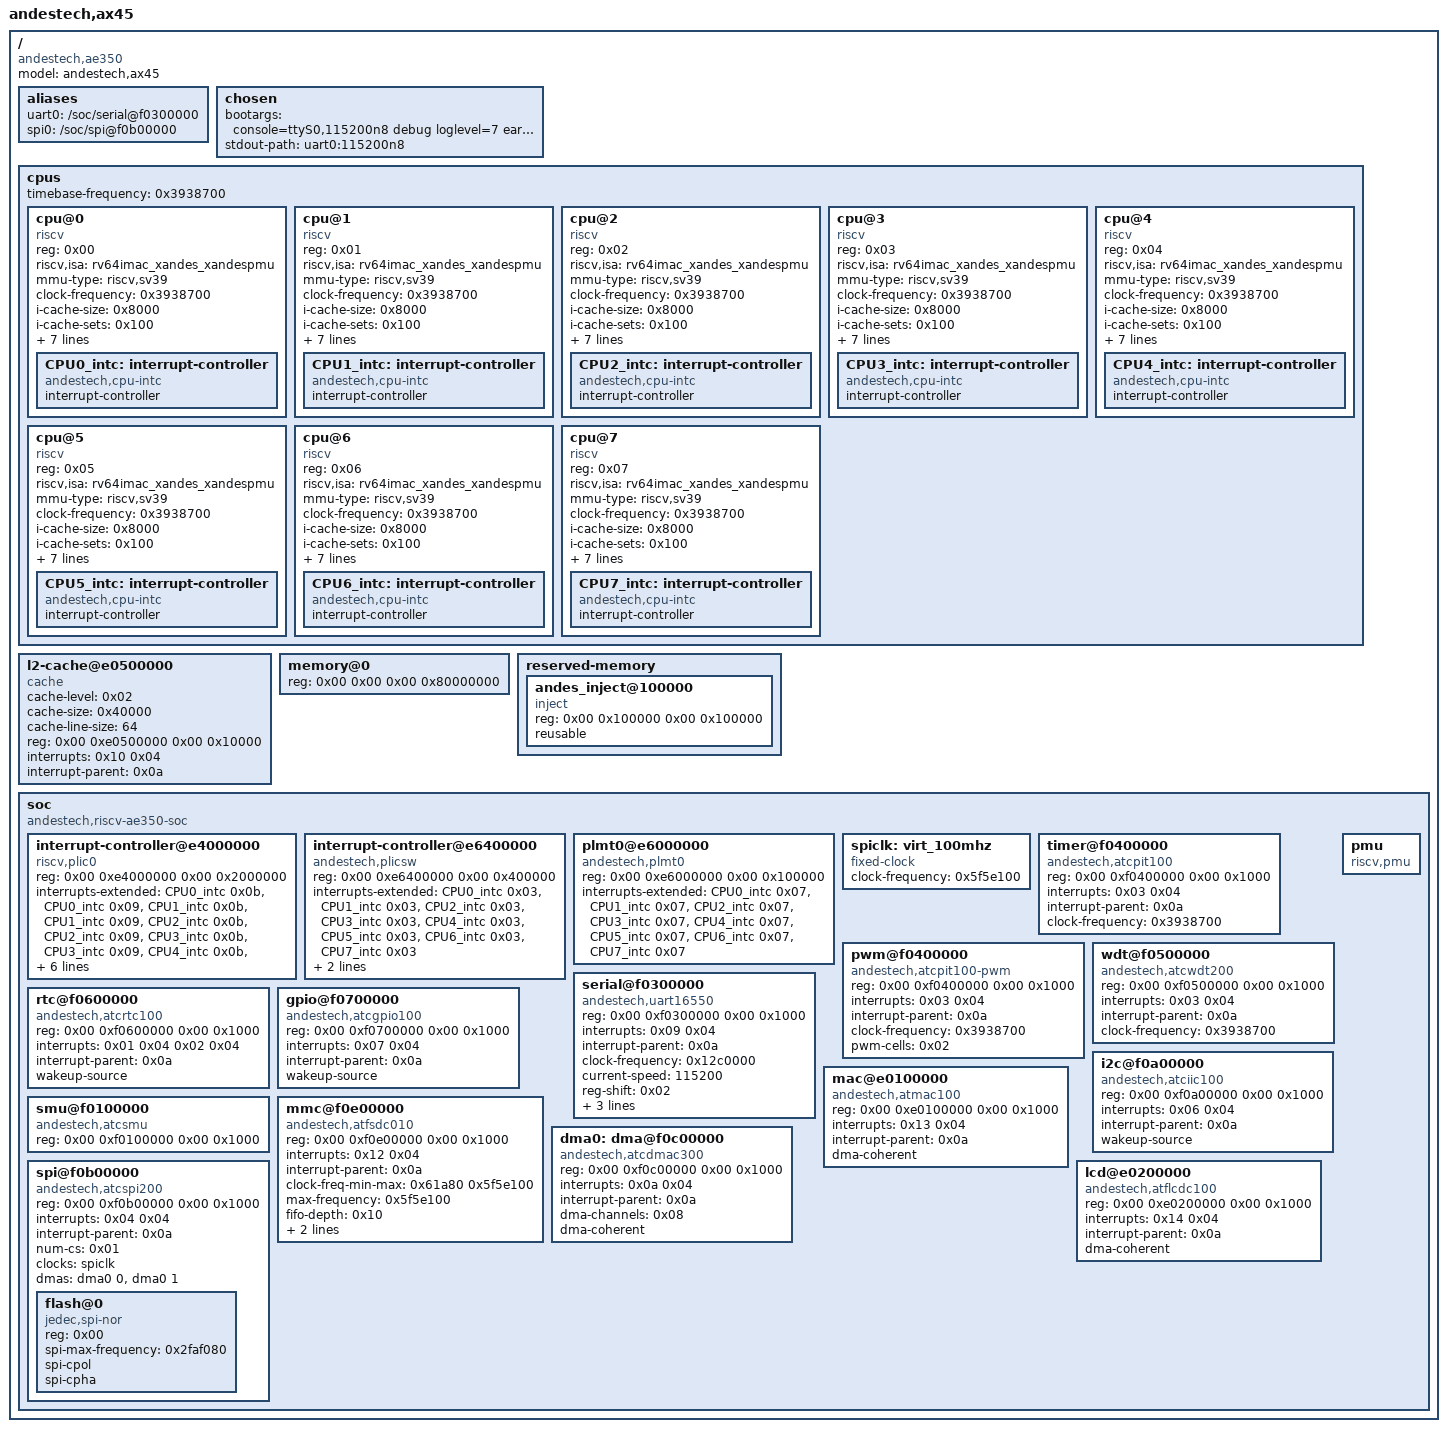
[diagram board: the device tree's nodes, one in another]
/dts-v1/;

/ {
	#address-cells = <0x02>;
	#size-cells = <0x02>;
	compatible = "andestech,ae350";
	model = "andestech,ax45";

	aliases {
		uart0 = "/soc/serial@f0300000";
		spi0 = "/soc/spi@f0b00000";
	};

	chosen {
		bootargs = "console=ttyS0,115200n8 debug loglevel=7 earlycon=sbi";
		stdout-path = "uart0:115200n8";
	};

	cpus {
		#address-cells = <0x01>;
		#size-cells = <0x00>;
		timebase-frequency = <0x3938700>;

		cpu@0 {
			device_type = "cpu";
			reg = <0x00>;
			status = "okay";
			compatible = "riscv";
			riscv,isa = "rv64imac_xandes_xandespmu";
			mmu-type = "riscv,sv39";
			clock-frequency = <0x3938700>;
			i-cache-size = <0x8000>;
			i-cache-sets = <0x100>;
			i-cache-line-size = <0x40>;
			i-cache-block-size = <0x40>;
			d-cache-size = <0x8000>;
			d-cache-sets = <0x80>;
			d-cache-line-size = <0x40>;
			d-cache-block-size = <0x40>;
			next-level-cache = <0x01>;

			CPU0_intc: interrupt-controller {
				#interrupt-cells = <0x01>;
				interrupt-controller;
				compatible = "andestech,cpu-intc", "riscv,cpu-intc";
			};
		};

		cpu@1 {
			device_type = "cpu";
			reg = <0x01>;
			status = "okay";
			compatible = "riscv";
			riscv,isa = "rv64imac_xandes_xandespmu";
			mmu-type = "riscv,sv39";
			clock-frequency = <0x3938700>;
			i-cache-size = <0x8000>;
			i-cache-sets = <0x100>;
			i-cache-line-size = <0x40>;
			i-cache-block-size = <0x40>;
			d-cache-size = <0x8000>;
			d-cache-sets = <0x80>;
			d-cache-line-size = <0x40>;
			d-cache-block-size = <0x40>;
			next-level-cache = <0x01>;

			CPU1_intc: interrupt-controller {
				#interrupt-cells = <0x01>;
				interrupt-controller;
				compatible = "andestech,cpu-intc", "riscv,cpu-intc";
			};
		};

		cpu@2 {
			device_type = "cpu";
			reg = <0x02>;
			status = "okay";
			compatible = "riscv";
			riscv,isa = "rv64imac_xandes_xandespmu";
			mmu-type = "riscv,sv39";
			clock-frequency = <0x3938700>;
			i-cache-size = <0x8000>;
			i-cache-sets = <0x100>;
			i-cache-line-size = <0x40>;
			i-cache-block-size = <0x40>;
			d-cache-size = <0x8000>;
			d-cache-sets = <0x80>;
			d-cache-line-size = <0x40>;
			d-cache-block-size = <0x40>;
			next-level-cache = <0x01>;

			CPU2_intc: interrupt-controller {
				#interrupt-cells = <0x01>;
				interrupt-controller;
				compatible = "andestech,cpu-intc", "riscv,cpu-intc";
			};
		};

		cpu@3 {
			device_type = "cpu";
			reg = <0x03>;
			status = "okay";
			compatible = "riscv";
			riscv,isa = "rv64imac_xandes_xandespmu";
			mmu-type = "riscv,sv39";
			clock-frequency = <0x3938700>;
			i-cache-size = <0x8000>;
			i-cache-sets = <0x100>;
			i-cache-line-size = <0x40>;
			i-cache-block-size = <0x40>;
			d-cache-size = <0x8000>;
			d-cache-sets = <0x80>;
			d-cache-line-size = <0x40>;
			d-cache-block-size = <0x40>;
			next-level-cache = <0x01>;

			CPU3_intc: interrupt-controller {
				#interrupt-cells = <0x01>;
				interrupt-controller;
				compatible = "andestech,cpu-intc", "riscv,cpu-intc";
			};
		};

		cpu@4 {
			device_type = "cpu";
			reg = <0x04>;
			status = "okay";
			compatible = "riscv";
			riscv,isa = "rv64imac_xandes_xandespmu";
			mmu-type = "riscv,sv39";
			clock-frequency = <0x3938700>;
			i-cache-size = <0x8000>;
			i-cache-sets = <0x100>;
			i-cache-line-size = <0x40>;
			i-cache-block-size = <0x40>;
			d-cache-size = <0x8000>;
			d-cache-sets = <0x80>;
			d-cache-line-size = <0x40>;
			d-cache-block-size = <0x40>;
			next-level-cache = <0x01>;

			CPU4_intc: interrupt-controller {
				#interrupt-cells = <0x01>;
				interrupt-controller;
				compatible = "andestech,cpu-intc", "riscv,cpu-intc";
			};
		};

		cpu@5 {
			device_type = "cpu";
			reg = <0x05>;
			status = "okay";
			compatible = "riscv";
			riscv,isa = "rv64imac_xandes_xandespmu";
			mmu-type = "riscv,sv39";
			clock-frequency = <0x3938700>;
			i-cache-size = <0x8000>;
			i-cache-sets = <0x100>;
			i-cache-line-size = <0x40>;
			i-cache-block-size = <0x40>;
			d-cache-size = <0x8000>;
			d-cache-sets = <0x80>;
			d-cache-line-size = <0x40>;
			d-cache-block-size = <0x40>;
			next-level-cache = <0x01>;

			CPU5_intc: interrupt-controller {
				#interrupt-cells = <0x01>;
				interrupt-controller;
				compatible = "andestech,cpu-intc", "riscv,cpu-intc";
			};
		};

		cpu@6 {
			device_type = "cpu";
			reg = <0x06>;
			status = "okay";
			compatible = "riscv";
			riscv,isa = "rv64imac_xandes_xandespmu";
			mmu-type = "riscv,sv39";
			clock-frequency = <0x3938700>;
			i-cache-size = <0x8000>;
			i-cache-sets = <0x100>;
			i-cache-line-size = <0x40>;
			i-cache-block-size = <0x40>;
			d-cache-size = <0x8000>;
			d-cache-sets = <0x80>;
			d-cache-line-size = <0x40>;
			d-cache-block-size = <0x40>;
			next-level-cache = <0x01>;

			CPU6_intc: interrupt-controller {
				#interrupt-cells = <0x01>;
				interrupt-controller;
				compatible = "andestech,cpu-intc", "riscv,cpu-intc";
			};
		};

		cpu@7 {
			device_type = "cpu";
			reg = <0x07>;
			status = "okay";
			compatible = "riscv";
			riscv,isa = "rv64imac_xandes_xandespmu";
			mmu-type = "riscv,sv39";
			clock-frequency = <0x3938700>;
			i-cache-size = <0x8000>;
			i-cache-sets = <0x100>;
			i-cache-line-size = <0x40>;
			i-cache-block-size = <0x40>;
			d-cache-size = <0x8000>;
			d-cache-sets = <0x80>;
			d-cache-line-size = <0x40>;
			d-cache-block-size = <0x40>;
			next-level-cache = <0x01>;

			CPU7_intc: interrupt-controller {
				#interrupt-cells = <0x01>;
				interrupt-controller;
				compatible = "andestech,cpu-intc", "riscv,cpu-intc";
			};
		};
	};

	l2-cache@e0500000 {
		compatible = "cache";
		cache-level = <0x02>;
		cache-size = <0x40000>;
		cache-line-size = <64>;
		reg = <0x00 0xe0500000 0x00 0x10000>;
		interrupts = <0x10 0x04>;
		interrupt-parent = <0x0a>;
		phandle = <0x01>;
	};

	memory@0 {
		reg = <0x00 0x00 0x00 0x80000000>;
		device_type = "memory";
	};

	reserved-memory {
		#address-cells = <2>;
		#size-cells = <2>;
		ranges;

		andes_inject@100000 {
			compatible = "inject";
			reg = <0x00 0x100000 0x00 0x100000>;
			reusable;
		};
	};

	soc {
		#address-cells = <0x02>;
		#size-cells = <0x02>;
		compatible = "andestech,riscv-ae350-soc","simple-bus";
		ranges;

		interrupt-controller@e4000000 {
			compatible = "riscv,plic0";
			reg = <0x00 0xe4000000 0x00 0x2000000>;
			interrupts-extended = <&CPU0_intc 0x0b &CPU0_intc 0x09 &CPU1_intc 0x0b &CPU1_intc 0x09 &CPU2_intc 0x0b &CPU2_intc 0x09 &CPU3_intc 0x0b &CPU3_intc 0x09 &CPU4_intc 0x0b &CPU4_intc 0x09 &CPU5_intc 0x0b &CPU5_intc 0x09 &CPU6_intc 0x0b &CPU6_intc 0x09 &CPU7_intc 0x0b &CPU7_intc 0x09>;
			interrupt-controller;
			#address-cells = <0x02>;
			#interrupt-cells = <0x02>;
			riscv,ndev = <0x47>;
			phandle = <0x0a>;
		};

		interrupt-controller@e6400000 {
			compatible = "andestech,plicsw";
			reg = <0x00 0xe6400000 0x00 0x400000>;
			interrupts-extended = <&CPU0_intc 0x03 &CPU1_intc 0x03 &CPU2_intc 0x03 &CPU3_intc 0x03 &CPU4_intc 0x03 &CPU5_intc 0x03 &CPU6_intc 0x03 &CPU7_intc 0x03>;
			interrupt-controller;
			#address-cells = <0x02>;
			#interrupt-cells = <0x02>;
			riscv,ndev = <0x08>;
		};

		plmt0@e6000000 {
			compatible = "andestech,plmt0";
			reg = <0x00 0xe6000000 0x00 0x100000>;
			interrupts-extended = <&CPU0_intc 0x07 &CPU1_intc 0x07 &CPU2_intc 0x07 &CPU3_intc 0x07 &CPU4_intc 0x07 &CPU5_intc 0x07 &CPU6_intc 0x07 &CPU7_intc 0x07>;
		};

		spiclk: virt_100mhz {
			compatible = "fixed-clock";
			#clock-cells = <0x00>;
			clock-frequency = <0x5f5e100>;
		};

		timer@f0400000 {
			compatible = "andestech,atcpit100";
			reg = <0x00 0xf0400000 0x00 0x1000>;
			interrupts = <0x03 0x04>;
			interrupt-parent = <0x0a>;
			clock-frequency = <0x3938700>;
		};

		pwm@f0400000 {
			compatible = "andestech,atcpit100-pwm";
			reg = <0x00 0xf0400000 0x00 0x1000>;
			interrupts = <0x03 0x04>;
			interrupt-parent = <0x0a>;
			clock-frequency = <0x3938700>;
			pwm-cells = <0x02>;
		};

		wdt@f0500000 {
			compatible = "andestech,atcwdt200";
			reg = <0x00 0xf0500000 0x00 0x1000>;
			interrupts = <0x03 0x04>;
			interrupt-parent = <0x0a>;
			clock-frequency = <0x3938700>;
		};

		serial@f0300000 {
			compatible = "andestech,uart16550", "ns16550a";
			reg = <0x00 0xf0300000 0x00 0x1000>;
			interrupts = <0x09 0x04>;
			interrupt-parent = <0x0a>;
			clock-frequency = <0x12c0000>;
			current-speed = <115200>;
			reg-shift = <0x02>;
			reg-offset = <0x20>;
			reg-io-width = <0x04>;
			no-loopback-test = <0x01>;
		};

		rtc@f0600000 {
			compatible = "andestech,atcrtc100";
			reg = <0x00 0xf0600000 0x00 0x1000>;
			interrupts = <0x01 0x04 0x02 0x04>;
			interrupt-parent = <0x0a>;
			wakeup-source;
		};

		gpio@f0700000 {
			compatible = "andestech,atcgpio100";
			reg = <0x00 0xf0700000 0x00 0x1000>;
			interrupts = <0x07 0x04>;
			interrupt-parent = <0x0a>;
			wakeup-source;
		};

		i2c@f0a00000 {
			compatible = "andestech,atciic100";
			reg = <0x00 0xf0a00000 0x00 0x1000>;
			interrupts = <0x06 0x04>;
			interrupt-parent = <0x0a>;
			wakeup-source;
		};

		mac@e0100000 {
			compatible = "andestech,atmac100";
			reg = <0x00 0xe0100000 0x00 0x1000>;
			interrupts = <0x13 0x04>;
			interrupt-parent = <0x0a>;
			dma-coherent;
		};

		smu@f0100000 {
			compatible = "andestech,atcsmu";
			reg = <0x00 0xf0100000 0x00 0x1000>;
		};

		mmc@f0e00000 {
			compatible = "andestech,atfsdc010";
			reg = <0x00 0xf0e00000 0x00 0x1000>;
			interrupts = <0x12 0x04>;
			interrupt-parent = <0x0a>;
			clock-freq-min-max = <0x61a80 0x5f5e100>;
			max-frequency = <0x5f5e100>;
			fifo-depth = <0x10>;
			dmas = <&dma0 0x09>;
			dma-names = "rxtx";
			dma-coherent;
		};

		dma0: dma@f0c00000 {
			compatible = "andestech,atcdmac300";
			reg = <0x00 0xf0c00000 0x00 0x1000>;
			interrupts = <0x0a 0x04>;
			interrupt-parent = <0x0a>;
			dma-channels = <0x08>;
			#dma-cells = <0x01>;
			dma-coherent;
		};

		lcd@e0200000 {
			compatible = "andestech,atflcdc100";
			reg = <0x00 0xe0200000 0x00 0x1000>;
			interrupts = <0x14 0x04>;
			interrupt-parent = <0x0a>;
			dma-coherent;
		};

		pmu {
			compatible = "riscv,pmu";
			device_type = "pmu";
		};

		spi@f0b00000 {
			compatible = "andestech,atcspi200";
			reg = <0x00 0xf0b00000 0x00 0x1000>;
			interrupts = <0x04 0x04>;
			interrupt-parent = <0x0a>;
			#address-cells = <0x01>;
			#size-cells = <0x00>;
			num-cs = <0x01>;
			clocks = <&spiclk>;
			dmas = <&dma0 0>, <&dma0 1>;
			dma-names = "spi_tx", "spi_rx";

			flash@0 {
				compatible = "jedec,spi-nor";
				reg = <0x00>;
				spi-max-frequency = <0x2faf080>;
				spi-cpol;
				spi-cpha;
			};
		};
	};
};
